# CC2538SF53 register map
File version: 1
CPU: CM3 r2p1, little endian, no MPU, no FPU, 3 interrupt priority bits
Registers are 32-bit, read-write, reset 0x0 unless marked. A register's access mark holds for its fields unless they carry their own. Offsets are from the block's base; lines under a group give offsets from that group; [hi:lo] are bit positions; {n}, {i} and the like mark numbered series; 'fields as' and 'values as' point back to an identical list; <NAME> marks a mode.

## Memory map
0x40008000 SSI0 size 0x1000
0x40009000 SSI1 size 0x1000
0x4000C000 UART0 size 0x1000
0x4000D000 UART1 size 0x1000
0x40020000 I2CM size 0x100
0x40020800 I2CS size 0x100
0x40030000 GPTIMER0 size 0x1000
0x40031000 GPTIMER1 size 0x1000
0x40032000 GPTIMER2 size 0x1000
0x40033000 GPTIMER3 size 0x1000
0x40088500 RFCORE_FFSM size 0x100
0x40088600 RFCORE_XREG size 0x200
0x40088800 RFCORE_SFR size 0x100
0x40089000 USB size 0x100
0x4008B000 AES size 0x1000
0x400D2000 SYS_CTRL size 0x100
0x400D3000 FLASH_CTRL size 0x100
0x400D4000 IOC size 0x154
0x400D5000 SMWDTHROSC size 0x100
0x400D6000 ANA_REGS size 0x100
0x400D7000 SOC_ADC size 0x100
0x400D9000 GPIO_A size 0x1000
0x400DA000 GPIO_B size 0x1000
0x400DB000 GPIO_C size 0x1000
0x400DC000 GPIO_D size 0x1000
0x400FF000 UDMA size 0x1000
0x40110000 STTEST size 0x100
0x44004000 PKA size 0x100
0x44010000 CCTEST size 0x100

## Interrupts
16 GPIO_A — GPIO_A global interrupt
17 GPIO_B — GPIO_B global interrupt
18 GPIO_C — GPIO_C global interrupt
19 GPIO_D — GPIO_D global interrupt
20 RESERVED_20 (SYS_CTRL) — Reserved global interrupt
21 UART0 — UART0 global interrupt
22 UART1 — UART1 global interrupt
23 SSI0 — SSI0 global interrupt
24 I2C (I2CM) — I2C global interrupt
25 RESERVED_25 (SYS_CTRL) — Reserved global interrupt
26 RESERVED_26 (SYS_CTRL) — Reserved global interrupt
27 RESERVED_27 (SYS_CTRL) — Reserved global interrupt
28 RESERVED_28 (SYS_CTRL) — Reserved global interrupt
29 RESERVED_29 (SYS_CTRL) — Reserved global interrupt
30 ADC (SYS_CTRL) — ADC interrupt
35 GPTIMER0A (GPTIMER0) — GPTIMER0A global interrupt
36 GPTIMER0B (GPTIMER0) — GPTIMER0B global interrupt
37 GPTIMER1A (GPTIMER1) — GPTIMER1A global interrupt
38 GPTIMER1B (GPTIMER1) — GPTIMER1B global interrupt
39 GPTIMER2A (GPTIMER2) — GPTIMER2A global interrupt
40 GPTIMER2B (GPTIMER2) — GPTIMER2B global interrupt
41 ANALOG_COMP (SOC_ADC) — ANALOG_COMP global interrupt
42 RF_TXRX_ALT (SYS_CTRL) — RF TX/RX (Alternate) global interrupt
43 RF_ERROR_ERR_ALT (SYS_CTRL) — RF Error (Alternate) global interrupt
44 SYS_CTRL — System Control global interrupt
45 FLASH_MEM_CTRL (SYS_CTRL) — Flash Memory Control global interrupt
46 AES_ALT (AES) — AES (Alternate) global interrupt
47 PKA_ALT (PKA) — PKA (Alternate) global interrupt
48 SM_TIMER_ALT (SYS_CTRL) — SM Timer (Alternate) global interrupt
49 MAC_TIMER_ALT (RFCORE_SFR) — MAC Timer (Alternate) global interrupt
50 SSI1 — SSI1 global interrupt
51 GPTIMER3A (GPTIMER3) — GPTIMER3A global interrupt
52 GPTIMER3B (GPTIMER3) — GPTIMER3B global interrupt
53 RESERVED_53 (SYS_CTRL) — Reserved global interrupt
55 RESERVED_55 (SYS_CTRL) — Reserved global interrupt
59 RESERVED_59 (SYS_CTRL) — Reserved global interrupt
60 RESERVED_60 (SYS_CTRL) — Reserved global interrupt
61 RESERVED_61 (SYS_CTRL) — Reserved global interrupt
62 UDMA_SW (UDMA) — UDMA software interrupt
63 UDMA_ERROR (UDMA) — UDMA error interrupt
{n} RESERVED_{n} (SYS_CTRL) (n=64..155) — Reserved global interrupt
156 USB (SYS_CTRL) — USB global interrupt
157 RF_TXRX (SYS_CTRL) — RF TX/RX global interrupt
158 RF_ERROR (SYS_CTRL) — RF ERROR global interrupt
159 AES (SYS_CTRL) — AES global interrupt
160 PKA (SYS_CTRL) — PKA global interrupt
161 SM_TIMER (SMWDTHROSC) — Sleep Timer global interrupt
162 MAC_TIMER (SYS_CTRL) — MAC_TIMER global interrupt
163 RESERVED_163 (SYS_CTRL) — Reserved global interrupt

## SMWDTHROSC
Base 0x400D5000
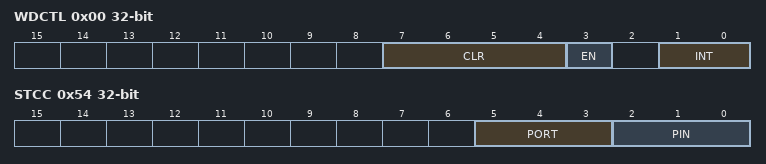
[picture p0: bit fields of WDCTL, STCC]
0x00 WDCTL — Watchdog Timer Control
  [7:4] CLR — Clear timer When 0xA followed by 0x5 is written to these bits, the timer is loaded with 0x0000. Note that 0x5 must be written within one watchdog clock period Twdt after 0xA was written for the clearing to take effect (ensured). If 0x5 is written between Twdt and 2Twdt after 0xA was written, the clearing may take effect, but there is no guarantee. If 0x5 is written > 2Twdt after 0xA was written, the timer will not be cleared. If a value other than 0x5 is written after 0xA has been written, the clear sequence is aborted. If 0xA is written, this starts a new clear sequence. Writing to these bits when EN = 0 has no effect.
  [3] EN — Enable timer When 1 is written to this bit the timer is enabled and starts incrementing. The interval setting specified by INT[1:0] is used. Writing 0 to this bit have no effect.
  [1:0] INT — Timer interval select These bits select the timer interval as follows: 00: Twdt x 32768 01: Twdt x 8192 10: Twdt x 512 11: Twdt x 64 Writing these bits when EN = 1 has no effect.
0x40 ST0 — Sleep Timer 0 count and compare
  [7:0] ST0 — Sleep Timer count and compare value. When read, this register returns the low bits [7:0] of the Sleep Timer count. When writing this register sets the low bits [7:0] of the compare value.
0x44 ST1 — Sleep Timer 1 count and compare
  [7:0] ST1 — Sleep Timer count and compare value When read, this register returns the middle bits [15:8] of the Sleep Timer count. When writing this register sets the middle bits [15:8] of the compare value. The value read is latched at the time of reading register ST0. The value written is latched when ST0 is written.
0x48 ST2 — Sleep Timer 2 count and compare
  [7:0] ST2 — Sleep Timer count and compare value When read, this register returns the high bits [23:16] of the Sleep Timer count. When writing this register sets the high bits [23:16] of the compare value. The value read is latched at the time of reading register ST0. The value written is latched when ST0 is written.
0x4C ST3 — Sleep Timer 3 count and compare
  [7:0] ST3 — Sleep Timer count and compare value When read, this register returns the high bits [31:24] of the Sleep Timer count. When writing this register sets the high bits [31:24] of the compare value. The value read is latched at the time of reading register ST0. The value written is latched when ST0 is written.
0x50 STLOAD ro — Sleep Timer load status
  [0] STLOAD — Status signal for when STx registers have been uploaded to 32-kHz counter. 1: Load is complete 0: Load is busy and STx regs are blocked for writing
0x54 STCC — Sleep Timer Capture control
  [5:3] PORT — Port select Valid settings are 0-3, all others inhibit any capture from occurring 000: Port A selected 001: Port B selected 010: Port C selected 011: Port D selected
  [2:0] PIN — Pin select Valid settings are 1-7 when either port A, B, C, or D is selected.
0x58 STCS — Sleep Timer Capture status
  [0] VALID — Capture valid flag Set to 1 when capture value in STCV has been updated Clear explicitly to allow new capture
{0x5C+4i} STCV{i} ro (i=0..2) — Sleep Timer Capture value byte {i}
  [7:0] STCV{i} — Bits [{8i+7}:{8i}] of Sleep Timer capture value
0x68 STCV3 ro — Sleep Timer Capture value byte 3
  [7:0] STCV3 — Bits [32:24] of Sleep Timer capture value
